# RL6678_IP_SVD register map
Vendor: Realtek
Registers are 32-bit, read-write, reset 0x0 unless marked. A register's access mark holds for its fields unless they carry their own. Offsets are from the block's base; [hi:lo] are bit positions.

## ZIGBEE_REG
Base 0x400F2000
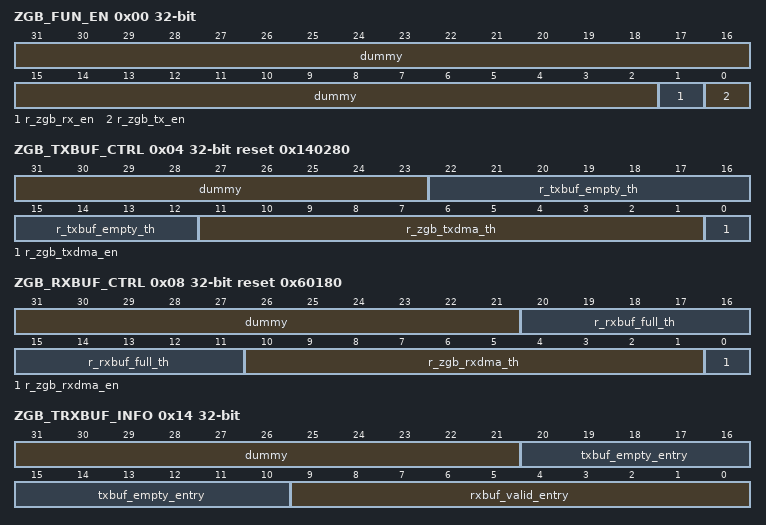
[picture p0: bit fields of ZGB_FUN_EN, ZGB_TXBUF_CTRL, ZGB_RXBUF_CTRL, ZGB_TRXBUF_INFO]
0x00 ZGB_FUN_EN — Zigbee Function enable
  [31:2] dummy
  [1] r_zgb_rx_en — zigbee mac rx enable
  [0] r_zgb_tx_en — zigbee mac tx enable
0x04 ZGB_TXBUF_CTRL reset 0x140280 — Zigbee Tx buffer control
  [31:23] dummy
  [22:12] r_txbuf_empty_th — when zigbee txbuf empty entry is large than the r_txbuf_empty_th, interrupt is issued to CPU half size of tx buffer:320,unit is 4byte
  [11:1] r_zgb_txdma_th — when r_zgb_txdma_en is 1 and zigbee txbuf empty entry is large than the r_zgb_txdma_th, dma_tx_req is raised to GDMA half size of tx buffer:320,unit is 4byte
  [0] r_zgb_txdma_en — GDMA enable for Zigbee Txbuf
0x08 ZGB_RXBUF_CTRL reset 0x60180 — Zigbee Rx buffer control
  [31:21] dummy
  [20:11] r_rxbuf_full_th — when zigbee rxbuf valid entry is large than the r_rxbuf_full_th, interrupt is issued to CPU half size of tx buffer:192,unit is 4byte
  [10:1] r_zgb_rxdma_th — when r_zgb_rxdma_en is 1 and zigbee rxbuf valid entry is large than the r_zgb_rxdma_th, dma_rx_req is raised to GDMA half size of tx buffer:192,unit is 4byte
  [0] r_zgb_rxdma_en — GDMA enable for Zigbee Rxbuf
0x0C ZGB_ISR0 ro — Zigbee Interrupt0 status
  [31:0] r_zgb_isr0 — interrupt status register of zigbee [31],WLAN2ZIGBEE_MAILBOX_INT, From Mailbox controller, 指示当前wlan fw 有向 mailbox(wlan->zigbee)写入信息 [30],BT_RX_STOP_INT, From PTA, BIT_BT_TX_START=(pre_gnt_bt_rx==1) &&(cur_gnt_bt_rx==0) [29],BT_RX_START_INT, From PTA, BIT_BT_TX_START=(pre_gnt_bt_rx==0) &&(cur_gnt_bt_rx==1) [28],BT_TX_STOP_INT, From PTA, BIT_BT_TX_START=(pre_gnt_bt_tx==1) &&(cur_gnt_bt_tx==0) [27],BT_TX_START_INT, From PTA, BIT_BT_TX_START=(pre_gnt_bt_tx==0) &&(cur_gnt_bt_tx==1) [26],WLAN_RX_STOP_INT, From wmac, BIT_WLAN_RX_START=(pre_wl_cca==1)&&(cur_wl_cca==0) [25],WLAN_RX_START_INT, From wmac, BIT_WLAN_RX_START=(pre_wl_cca==0)&&(cur_wl_cca==1), Zigbee 收到该中断后,可以选择是否要中断当前封包TX or RX [24],WLAN_TX_STOP_INT, From wmac, BIT_WLAN_TX_START=(pre_wl_mactxen==1)&&(cur_wl_mactxen=0) [23],WLAN_TX_START_INT, From wmac, BIT_WLAN_TX_START=(pre_wl_mactxen==0)&&(cur_wl_mactxen=1), Zigbee 收到该中断后,可以选择是否要中断当前封包TX or RX [22],DIS_GNT_ZIGBEE_TX_INT, From PTA, BIT_DIS_GNT_ZIGBEE_TX=(pre_gnt_zigbee_tx==1)&& (cur_gnt_zigbee_tx==0) [21],GNT_ZIGBEE_TX_INT, From PTA, BIT_GNT_ZIGBEE_TX=(pre_gnt_zigbee_tx==0)&& (cur_gnt_zigbee_tx==1) [20:15],dummy [14],INTER_ZIGBEE_RFGAIN_CHANGED, zigbee_rfgain_changed posedge pulse [13],INTER_ZIGBEE_AAGC_DONE, zigbee_aagcrdy posedge pulse [12],rxbuf_underflow, when read rxbuf and txbuf is empty [11],rxbuf_empty, when rxbuf is empty [10],rxbuf_overflow, when write rxbuf and rxbuf is full [9],rxbuf_full, when rxbuf is full [8],INTER_ZIGBEE_RXBUF_ALMOST_FULL, when zigbee rxbuf valid entry is large than the r_rxbuf_full_th [7:6],dummy [5],INTER_ZIGBEE_TX_STOP, zigbee_rftxen negedege pulse [4],txbuf_overflow, when wirte txbuf and txbuf is full [3],txbuf_full, when txbuf is full [2],txbuf_underflow, when read txbuf and txbuf is empty [1],txbuf_empty, when txbuf is empty [0],INTER_ZIGBEE_TXBUF_ALMOST_EMPTY, when zigbee txbuf empty entry is large than the r_txbuf_empty_th
0x10 ZGB_IMR0 — Zigbee Interrupt0 mask
  [31:0] r_zgb_imr0 — interrupt mask register of zigbee
0x14 ZGB_TRXBUF_INFO access per field — Zigbee Tx/Rx buffer information
  [31:21] dummy rw
  [20:10] txbuf_empty_entry ro — empty entry size of txbuf, unit is 4byte
  [9:0] rxbuf_valid_entry ro — valid entry size of rxbuf, unit is 4byte
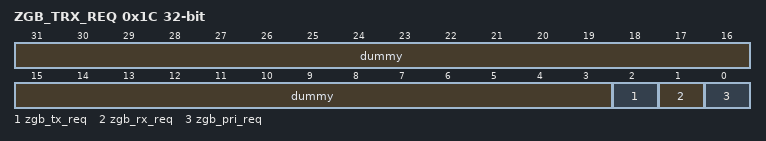
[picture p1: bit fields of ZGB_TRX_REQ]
0x1C ZGB_TRX_REQ — Zigbee Tx/Rx/pri request
  [31:3] dummy
  [2] zgb_tx_req — zigbee tx request
  [1] zgb_rx_req — zigbee rx request
  [0] zgb_pri_req — zigbee priority request
0x20 ZGB_ISR1 ro — Zigbee Interrupt1 status
  [31:0] r_zgb_isr1 — interrupt status register of zigbee [31:8],dummy [7:0],INTER_ZIGBEE_INTR_O, zigbee_intr_o[7:0] posedge pulse
0x24 ZGB_IMR1 — Zigbee Interrupt1 mask
  [31:0] r_zgb_imr1 — interrupt mask register of zigbee
